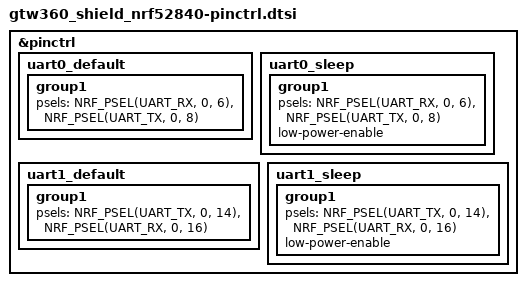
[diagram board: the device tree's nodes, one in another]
/*
 * SPDX-FileCopyrightText: Copyright The Zephyr Project Contributors
 * SPDX-License-Identifier: Apache-2.0
 */

&pinctrl {
	/* The console */
	uart0_default: uart0_default {
		group1 {
			psels = <NRF_PSEL(UART_RX, 0, 6)>, <NRF_PSEL(UART_TX, 0, 8)>;
		};
	};

	uart0_sleep: uart0_sleep {
		group1 {
			psels = <NRF_PSEL(UART_RX, 0, 6)>, <NRF_PSEL(UART_TX, 0, 8)>;
			low-power-enable;
		};
	};

	/* The link to the host of the gateway */
	uart1_default: uart1_default {
		group1 {
			psels = <NRF_PSEL(UART_TX, 0, 14)>, <NRF_PSEL(UART_RX, 0, 16)>;
		};
	};

	uart1_sleep: uart1_sleep {
		group1 {
			psels = <NRF_PSEL(UART_TX, 0, 14)>, <NRF_PSEL(UART_RX, 0, 16)>;
			low-power-enable;
		};
	};
};
